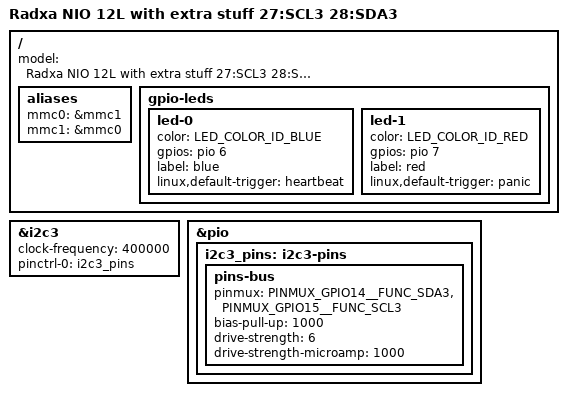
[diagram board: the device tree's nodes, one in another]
// SPDX-License-Identifier: (GPL-2.0+ OR MIT)

/dts-v1/;

#include "mt8395-radxa-nio-12l.dts"

/ {
	model = "Radxa NIO 12L with extra stuff 27:SCL3 28:SDA3";
	// See https://docs.radxa.com/en/nio/nio12l/hardware-design/hardware-interface#40-pin-gpio-header

	aliases {
		mmc0 = &mmc1; // sdcard - always present - matches u-boot
		mmc1 = &mmc0; // emmc - not on UFS models
	};

	// label and make blue led heartbeat, red led pan
	gpio-leds {
		led-0 {
			color = <LED_COLOR_ID_BLUE>;
			gpios = <&pio 6 GPIO_ACTIVE_HIGH>;
			label = "blue";
			linux,default-trigger = "heartbeat";
		};

		led-1 {
			color = <LED_COLOR_ID_RED>;
			gpios = <&pio 7 GPIO_ACTIVE_HIGH>;
			label = "red";
			linux,default-trigger = "panic";
		};
	};


};

/* Exposed on 40-pin header (blue-colored pins 27:SCL3 28:SDA3) - aliased to i2c1 in Collabora/upstream DT */
&i2c3 {
	clock-frequency = <400000>;
	pinctrl-0 = <&i2c3_pins>;
	pinctrl-names = "default";
	status = "okay";
};


&pio {
	i2c3_pins: i2c3-pins {
		pins-bus {
			pinmux = <PINMUX_GPIO14__FUNC_SDA3>,
				 <PINMUX_GPIO15__FUNC_SCL3>;
			bias-pull-up = <1000>;
			drive-strength = <6>;
			drive-strength-microamp = <1000>;
		};
	};
};
